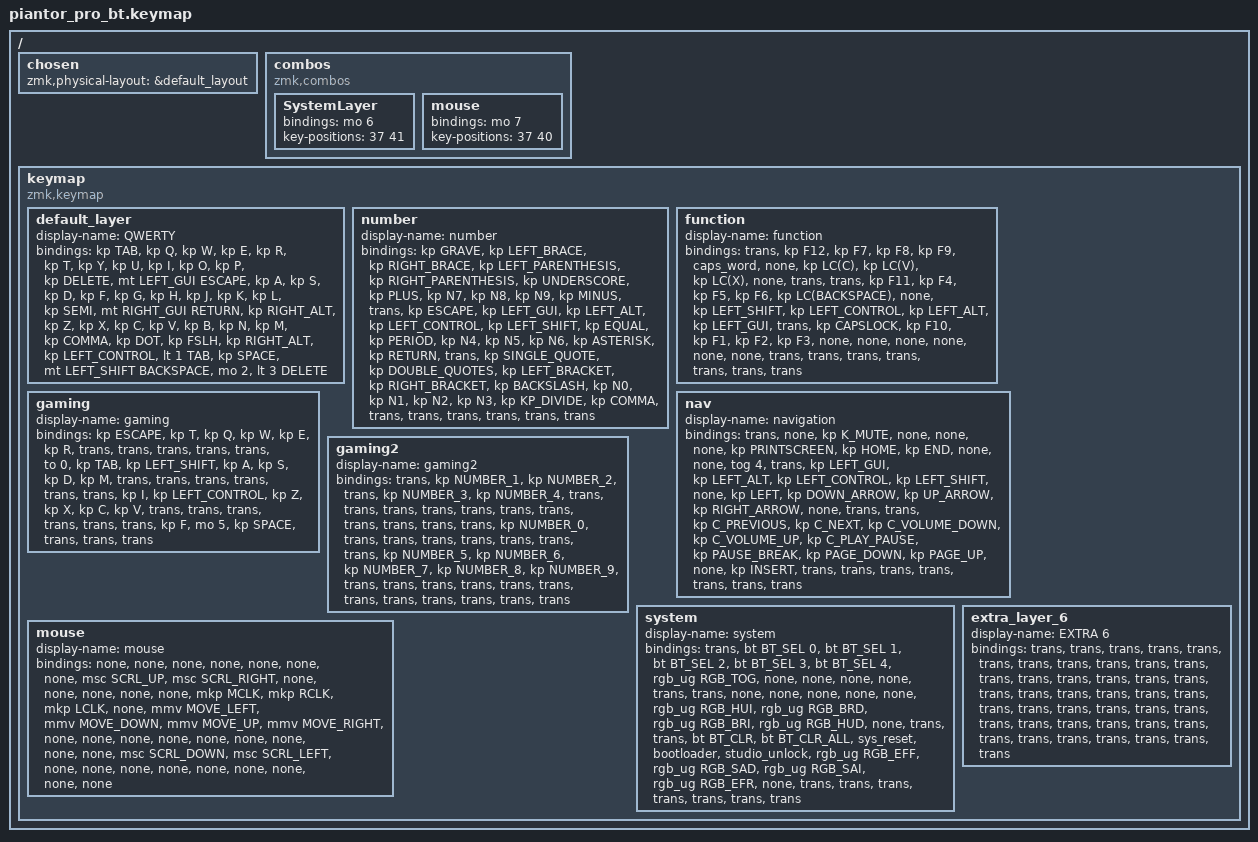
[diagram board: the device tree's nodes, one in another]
/*
 * Copyright (c) 2020 The ZMK Contributors
 *
 * SPDX-License-Identifier: MIT
 */

#include <behaviors.dtsi>
#include <dt-bindings/zmk/bt.h>
#include <dt-bindings/zmk/keys.h>
#include <dt-bindings/zmk/pointing.h>
#include <dt-bindings/zmk/rgb.h>

/ {
    chosen { zmk,physical-layout = &default_layout; };
};

/ {
    combos {
        compatible = "zmk,combos";

        SystemLayer {
            bindings = <&mo 6>;
            key-positions = <37 41>;
        };

        mouse {
            bindings = <&mo 7>;
            key-positions = <37 40>;
        };
    };

    keymap {
        compatible = "zmk,keymap";

        default_layer {
            display-name = "QWERTY";

            // --------------------------------------------------------------------------------
            // |  TAB |  Q  |  W  |  E  |  R  |  T  |  Y  |  U   |  I  |  O  |  P  | BSPC |
            // | CTRL |  A  |  S  |  D  |  F  |  G  |  H  |  J   |  K  |  L  |  ;  |  '   |
            // | SHFT |  Z  |  X  |  C  |  V  |  B  |  N  |  M   |  ,  |  .  |  /  | ESC  |
            //                    | GUI | LWR | SPC | ENT | RSE  | ALT |

            bindings = <
&kp TAB  &kp Q  &kp W  &kp E  &kp R  &kp T  &kp Y  &kp U  &kp I  &kp O  &kp P  &kp DELETE  &mt LEFT_GUI ESCAPE  &kp A  &kp S  &kp D  &kp F  &kp G  &kp H  &kp J  &kp K  &kp L  &kp SEMI  &mt RIGHT_GUI RETURN  &kp RIGHT_ALT  &kp Z  &kp X  &kp C  &kp V  &kp B  &kp N  &kp M  &kp COMMA  &kp DOT  &kp FSLH  &kp RIGHT_ALT  &kp LEFT_CONTROL  &lt 1 TAB  &kp SPACE  &mt LEFT_SHIFT BACKSPACE  &mo 2  &lt 3 DELETE
            >;
        };

        number {
            display-name = "number";

            // -----------------------------------------------------------------------------------------
            // |  TAB |  !  |  @  |  #  |  $  |  %  |  ^  |  &  |  *  |  (  |  )  | BSPC |
            // | CTRL |     |     |     |     |     |  -  |  =  |  [  |  ]  |  \  |  `   |
            // | SHFT |     |     |     |     |     |  _  |  +  |  {  |  }  | "|" |  ~   |
            //                    | GUI |     | SPC | ENT |     | ALT |

            bindings = <
&kp GRAVE  &kp LEFT_BRACE  &kp RIGHT_BRACE  &kp LEFT_PARENTHESIS  &kp RIGHT_PARENTHESIS  &kp UNDERSCORE  &kp PLUS  &kp N7  &kp N8  &kp N9  &kp MINUS  &trans  &kp ESCAPE  &kp LEFT_GUI  &kp LEFT_ALT  &kp LEFT_CONTROL  &kp LEFT_SHIFT  &kp EQUAL  &kp PERIOD  &kp N4  &kp N5  &kp N6  &kp ASTERISK  &kp RETURN  &trans  &kp SINGLE_QUOTE  &kp DOUBLE_QUOTES  &kp LEFT_BRACKET  &kp RIGHT_BRACKET  &kp BACKSLASH  &kp N0  &kp N1  &kp N2  &kp N3  &kp KP_DIVIDE  &kp COMMA  &trans  &trans  &trans  &trans  &trans  &trans
            >;
        };

        function {
            display-name = "function";
            bindings = <
&trans  &kp F12  &kp F7  &kp F8  &kp F9  &caps_word  &none  &kp LC(C)  &kp LC(V)  &kp LC(X)  &none  &trans  &trans  &kp F11  &kp F4  &kp F5  &kp F6  &kp LC(BACKSPACE)  &none  &kp LEFT_SHIFT  &kp LEFT_CONTROL  &kp LEFT_ALT  &kp LEFT_GUI  &trans  &kp CAPSLOCK  &kp F10  &kp F1  &kp F2  &kp F3  &none  &none  &none  &none  &none  &none  &trans  &trans  &trans  &trans  &trans  &trans  &trans
            >;
        };

        nav {
            display-name = "navigation";

            // -----------------------------------------------------------------------------------------
            // |  TAB |  1  |  2  |  3  |  4  |  5    |  6  |  7  |  8  |  9  |  0  | BSPC |
            // | CTRL | BT1 | BT2 | BT3 | BT4 | BT5   | LFT | DWN |  UP | RGT |     |      |
            // | SHFT | BTCR| RGB | RST | BOOT| Unlock|     |     |     |     |     |      |
            //                    | GUI |     | SPC   | ENT |     | ALT |

            bindings = <
&trans  &none  &kp K_MUTE  &none  &none  &none  &kp PRINTSCREEN  &kp HOME  &kp END  &none  &none  &tog 4  &trans  &kp LEFT_GUI  &kp LEFT_ALT  &kp LEFT_CONTROL  &kp LEFT_SHIFT  &none  &kp LEFT  &kp DOWN_ARROW  &kp UP_ARROW  &kp RIGHT_ARROW  &none  &trans  &trans  &kp C_PREVIOUS  &kp C_NEXT  &kp C_VOLUME_DOWN  &kp C_VOLUME_UP  &kp C_PLAY_PAUSE  &kp PAUSE_BREAK  &kp PAGE_DOWN  &kp PAGE_UP  &none  &kp INSERT  &trans  &trans  &trans  &trans  &trans  &trans  &trans
            >;
        };

        gaming {
            display-name = "gaming";
            bindings = <
&kp ESCAPE  &kp T  &kp Q  &kp W  &kp E  &kp R  &trans  &trans  &trans  &trans  &trans  &to 0  &kp TAB  &kp LEFT_SHIFT  &kp A  &kp S  &kp D  &kp M  &trans  &trans  &trans  &trans  &trans  &trans  &kp I  &kp LEFT_CONTROL  &kp Z  &kp X  &kp C  &kp V  &trans  &trans  &trans  &trans  &trans  &trans  &kp F  &mo 5  &kp SPACE  &trans  &trans  &trans
            >;
        };

        gaming2 {
            display-name = "gaming2";
            bindings = <
&trans  &kp NUMBER_1  &kp NUMBER_2  &trans  &kp NUMBER_3  &kp NUMBER_4  &trans  &trans  &trans  &trans  &trans  &trans  &trans  &trans  &trans  &trans  &trans  &kp NUMBER_0  &trans  &trans  &trans  &trans  &trans  &trans  &trans  &kp NUMBER_5  &kp NUMBER_6  &kp NUMBER_7  &kp NUMBER_8  &kp NUMBER_9  &trans  &trans  &trans  &trans  &trans  &trans  &trans  &trans  &trans  &trans  &trans  &trans
            >;
        };

        system {
            display-name = "system";
            bindings = <
&trans  &bt BT_SEL 0  &bt BT_SEL 1  &bt BT_SEL 2  &bt BT_SEL 3  &bt BT_SEL 4  &rgb_ug RGB_TOG  &none  &none  &none  &none  &trans  &trans  &none  &none  &none  &none  &none  &rgb_ug RGB_HUI  &rgb_ug RGB_BRD  &rgb_ug RGB_BRI  &rgb_ug RGB_HUD  &none  &trans  &trans  &bt BT_CLR  &bt BT_CLR_ALL  &sys_reset  &bootloader  &studio_unlock  &rgb_ug RGB_EFF  &rgb_ug RGB_SAD  &rgb_ug RGB_SAI  &rgb_ug RGB_EFR  &none  &trans  &trans  &trans  &trans  &trans  &trans  &trans
            >;
        };

        mouse {
            display-name = "mouse";
            bindings = <
&none  &none  &none  &none  &none  &none  &none  &msc SCRL_UP  &msc SCRL_RIGHT  &none  &none  &none  &none  &none  &mkp MCLK  &mkp RCLK  &mkp LCLK  &none  &mmv MOVE_LEFT  &mmv MOVE_DOWN  &mmv MOVE_UP  &mmv MOVE_RIGHT  &none  &none  &none  &none  &none  &none  &none  &none  &none  &msc SCRL_DOWN  &msc SCRL_LEFT  &none  &none  &none  &none  &none  &none  &none  &none  &none
            >;
        };

        extra_layer_6 {
            display-name = "EXTRA 6";
            bindings = <
&trans  &trans  &trans  &trans  &trans  &trans  &trans  &trans  &trans  &trans  &trans  &trans  &trans  &trans  &trans  &trans  &trans  &trans  &trans  &trans  &trans  &trans  &trans  &trans  &trans  &trans  &trans  &trans  &trans  &trans  &trans  &trans  &trans  &trans  &trans  &trans  &trans  &trans  &trans  &trans  &trans  &trans
            >;
        };
    };
};
